# NUC029AN_v1 register map
File version: 1.0
Registers are 32-bit, read-write, reset 0x0 unless marked. A register's access mark holds for its fields unless they carry their own. Offsets are from the block's base; [hi:lo] are bit positions; {n}, {i} and the like mark numbered series.

## GCR — GCR Register Map
Base 0x50000000
0x00 PDID ro reset 0x20005200 — Part Device Identification number Register
  [31:0] PDID — Part Device Identification Number. This register reflects device part number code. S/W can read this register to identify which device is used. For example, M052LCN PDID code is 0x2000_5200.
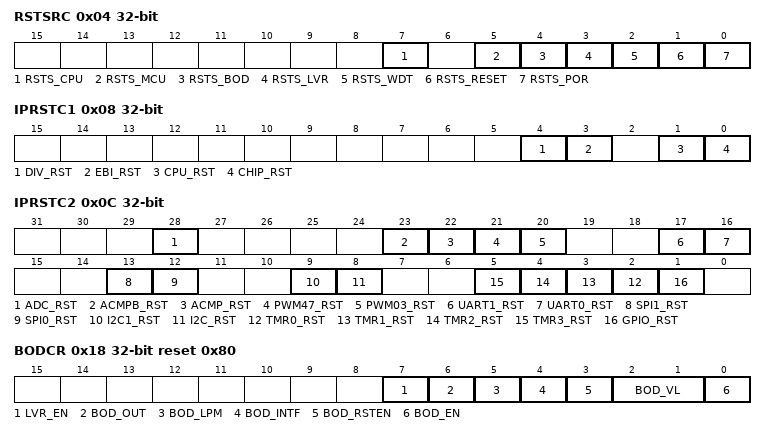
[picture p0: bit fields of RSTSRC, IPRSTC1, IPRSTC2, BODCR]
0x04 RSTSRC (reset mask 0xFFFFFF00) — System Reset Source Register
  [7] RSTS_CPU — The RSTS_CPU flag is set by hardware if software writes CPU_RST (IPRSTC1[1]) 1 to reset Cortex-M0 CPU kernel and Flash memory controller (FMC). Software can write 1 to clear this bit to zero.
    0=No reset from CPU; 1=The Cortex-M0 CPU kernel and FMC are reset by software setting CPU_RST to 1
  [5] RSTS_MCU — The RSTS_MCU flag is set by the "reset signal" from the MCU Cortex_M0 kernel to indicate the previous reset source. This bit is cleared by writing 1 to itself.
    0=No reset from MCU; 1=The MCU Cortex_M0 had issued the reset signal to reset the system by software writing 1 to bit SYSRESTREQ(AIRCR[2], Application Interrupt and Reset Control Register) in system control registers of Cortex_M0 kernel
  [4] RSTS_BOD — The RSTS_BOD flag is set by the "reset signal" from the Brown-Out Detector to indicate the previous reset source. Software can write 1 to clear this bit to zero.
    0=No reset from BOD; 1=The Brown-Out Detector module had issued the reset signal to reset the system
  [3] RSTS_LVR — The RSTS_LVR flag is set by the "reset signal" from the Low-Voltage-Reset controller to indicate the previous reset source. Software can write 1 to clear this bit to zero.
    0=No reset from LVR; 1=The LVR module had issued the reset signal to reset the system
  [2] RSTS_WDT — The RSTS_WDT flag is set by the "reset signal" from the Watchdog timer to indicate the previous reset source. Software can write 1 to clear this bit to zero.
    0=No reset from Watchdog timer; 1=The Watchdog timer had issued the reset signal to reset the system
  [1] RSTS_RESET — The RSTS_RESET flag is set by the "reset signal" from the /RESET pin to indicate the previous reset source. Software can write 1 to clear this bit to zero.
    0=No reset from Pin /RESET; 1=The Pin /RESET had issued the reset signal to reset the system
  [0] RSTS_POR — The RSTS_POR flag is set by the "reset signal", which is from the Power-On Reset (POR) module or bit CHIP_RST (IPRSTC1[0]) is set, to indicate the previous reset source. Software can write 1 to clear this bit to zero.
    0=No reset from POR or CHIP_RST; 1=The Power-On-Reset (POR) or CHIP_RST had issued the reset signal to reset the system
0x08 IPRSTC1 — Peripheral Reset Control Register 1
  [4] DIV_RST — DIV Controller Reset (write-protection bit). Set this bit to 1 will generate a reset signal to the DIVIDER. User need to set this bit to 0 to release from the reset state. This bit is the protected bit, It means programming this bit needs to write "59h", "16h", "88h" to address 0x5000_0100 to disable register protection. Reference the register REGWRPROT at address GCR_BA+0x100
    0=DIVIDER controller normal operation; 1=DIVIDER controller reset
  [3] EBI_RST — EBI Controller Reset (write-protected). Set these bit "1" will generate a reset signal to the EBI. User need to set this bit to "0" to release from the reset state
    0=EBI controller normal operation; 1=EBI controller reset
  [1] CPU_RST — CPU kernel one shot reset (write-protected). Set this bit will reset the Cortex-M0 CPU kernel and Flash memory controller (FMC). This bit will automatically return to "0" after the 2 clock cycles
    0=Normal; 1=Reset CPU
  [0] CHIP_RST — CHIP one shot reset (write-protected). Set this bit will reset the CHIP, including CPU kernel and all peripherals, and this bit will automatically return to "0" after the 2 clock cycles. The CHIP_RST is same as the POR reset , all the chip module is reset and the chip setting from flash are also reload
    0=Normal; 1=Reset CHIP
0x0C IPRSTC2 — Peripheral Reset Control Register 2
  [28] ADC_RST — ADC Controller Reset
    0=ADC controller normal operation; 1=ADC controller reset
  [23] ACMPB_RST — Analog Comparator 1 Controller Reset
    0=Analog Comparator controller 1 normal operation; 1=Analog Comparator controller 1 reset
  [22] ACMP_RST — Analog Comparator Controller Reset
    0=Analog Comparator controller normal operation; 1=Analog Comparator controller reset
  [21] PWM47_RST — PWM4~7 controller Reset
    0=PWM4~7 controller normal operation; 1=PWM4~7 controller reset
  [20] PWM03_RST — PWM0~3 controller Reset
    0=PWM0~3 controller normal operation; 1=PWM0~3 controller reset
  [17] UART1_RST — UART1 controller Reset
    0=UART1 controller normal operation; 1=UART1 controller reset
  [16] UART0_RST — UART0 controller Reset
    0=UART0 controller normal operation; 1=UART0 controller reset
  [13] SPI1_RST — SPI1 controller Reset
    0=SPI1 controller normal operation; 1=SPI1 controller reset
  [12] SPI0_RST — SPI0 controller Reset
    0=SPI0 controller normal operation; 1=SPI0 controller reset
  [9] I2C1_RST — I2C1 controller Reset
    0=I2C1 controller normal operation; 1=I2C1 controller reset
  [8] I2C_RST — I2C0 controller Reset
    0=I2C0 controller normal operation; 1=I2C0 controller reset
  [n+2] TMR{n}_RST (n=0..3) — Timer{n} controller Reset
    0=Timer{n} controller normal operation; 1=Timer{n} controller reset
  [1] GPIO_RST — GPIO (P0~P4) controller Reset
    0=GPIO controller normal operation; 1=GPIO controller reset
0x18 BODCR reset 0x80 (reset mask 0xFFFFFFF0) — Brown-Out Detector Control Register
  [7] LVR_EN — Low Voltage Reset Enable (write-protected). The LVR function reset the chip when the input power voltage is lower than LVR circuit setting. LVR function is enabled in default.
    0=Disabled Low Voltage Reset function; 1=Enabled Low Voltage Reset function - After enabling the bit, the LVR function will be active with 100uS delay for LVR output stable. (Default)
  [6] BOD_OUT — Brown-Out Detector output status
    0=Brown-Out Detector output status is 0. It means the detected voltage is higher than BOD_VL setting or BOD_EN is 0; 1=Brown-Out Detector output status is 1. It means the detected voltage is lower than BOD_VL setting. If the BOD_EN is 0, BOD function disabled , this bit always responds 0
  [5] BOD_LPM — Brown-Out Detector Low power Mode (write-protected). The BOD consumes about 100uA in normal mode, the low power mode can reduce the current to about 1/10 but slow the BOD response.
    0=BOD operate in normal mode (default); 1=Enable the BOD low power mode
  [4] BOD_INTF — Brown-Out Detector Interrupt Flag. Software can write 1 to clear this bit to zero.
    0=Brown-Out Detector does not detect any voltage draft at VDD down through or up through the voltage of BOD_VL setting; 1=When Brown-Out Detector detects the VDD is dropped down through the voltage of BOD_VL setting or the VDD is raised up through the voltage of BOD_VL setting, this bit is set to 1 and the Brown-Out interrupt is requested if Brown-Out interrupt is enabled
  [3] BOD_RSTEN — Brown-Out Reset Enable (write-protected). The default value is set by flash controller user configuration register config0 bit[20].
    0=Enable the Brown-Out "INTERRUPT" function.While the BOD function is enabled (BOD_EN high) and BOD interrupt function is enabled (BOD_RSTEN low), BOD will assert an interrupt if BOD_OUT is high. BOD interrupt will keep till to the BOD_EN set to 0. BOD interrupt can be blocked by disabling the NVIC BOD interrupt or disabling BOD function (set BOD_EN low); 1=Enable the Brown-Out "RESET" function. While the Brown-Out Detector function is enabled (BOD_EN high) and BOD reset function is enabled (BOD_RSTEN high), BOD will assert a signal to reset chip when the detected voltage is lower than the threshold (BOD_OUT high)
  [2:1] BOD_VL — Brown-Out Detector Threshold Voltage Selection (write-protected)
  [0] BOD_EN — Brown-Out Detector Enable (write-protected). The default value is set by flash controller user configuration register config0 bit[23]
    0=Brown-Out Detector function is disabled; 1=Brown-Out Detector function is enabled
0x1C TEMPCR — Temperature Sensor Control Register
  [0] VTEMP_EN — Temperature sensor Enable. This bit is used to enable/disable temperature sensor function. After this bit is set to 1, the value of temperature can get from ADC conversion result by ADC channel selecting channel 7 and alternative multiplexer channel selecting temperature sensor. Detail ADC conversion function please reference ADC function chapter.
    0=Disabled temperature sensor function (default); 1=Enabled temperature sensor function
0x24 PORCR (reset mask 0xFFFFFF00) — Power-On-Reset Controller Register
  [15:0] POR_DIS_CODE — Power-On-Reset enable control (write-protected). When power on, the POR circuit generates a reset signal to reset the whole chip function, but noise on the power may cause the POR active again. If set the POR_DIS_CODE equal to 0x5AA5, the POR reset function will be disabled and the POR function will re-active till the power voltage is lower to set the POR_DIS_CODE to another value or reset by chip other reset function. Include: /RESET, Watch dog, LVR reset BOD reset, ICE reset command and the software-chip reset function.
0x28 GPIO_2CKn — GPIO 2CK Strong Pull High Controller Register
  [0] GPIO_2CKn — GPIO two clock strong pull high disable
    0=GPIO two clock strong pull high is enabled if Pxx_DOUT is 0 before reset; 1=GPIO two clock strong pull high is disabled if Pxx_DOUT is 0 before reset
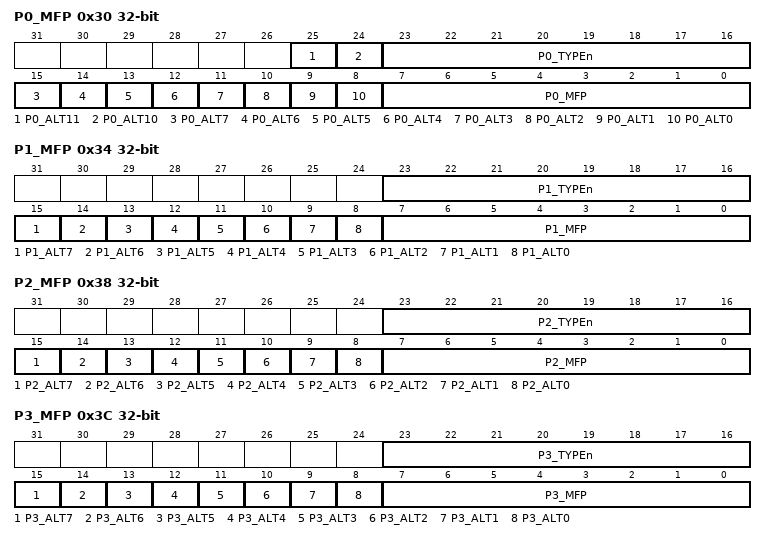
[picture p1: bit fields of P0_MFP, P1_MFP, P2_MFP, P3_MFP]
0x30 P0_MFP — P0 multiple function and input type control register
  [25] P0_ALT11 — P0.1 alternate function Selection1. The pin function of P0.1 depends on P0_MFP[1], P0_ALT[1], and P0_ALT1[1]. Refer to P0_ALT[1] for details descriptions.
  [24] P0_ALT10 — P0.0 alternate function Selection1. The pin function of P0.0 depends on P0_MFP[0], P0_ALT[0], and P0_ALT1[0]. Refer to P0_ALT[0] for details descriptions.
  [23:16] P0_TYPEn — P0[7:0] input Schmitt Trigger function Enable
    0=Disable P0[7:0] I/O input Schmitt Trigger function; 1=Enable P0[7:0] I/O input Schmitt Trigger function
  [15] P0_ALT7 — P0.7 alternate function Selection
  [14] P0_ALT6 — P0.6 alternate function Selection
  [13] P0_ALT5 — P0.5 alternate function Selection
  [12] P0_ALT4 — P0.4 alternate function Selection
  [11] P0_ALT3 — P0.3 alternate function Selection
  [10] P0_ALT2 — P0.2 alternate function Selection
  [9] P0_ALT1 — P0.1 alternate function Selection
  [8] P0_ALT0 — P0.0 alternate function Selection
  [7:0] P0_MFP — P0 multiple function Selection. The pin function of P0 depends on P0_MFP and P0_ALT. Refer to P0_ALT for details descriptions.
0x34 P1_MFP — P1 multiple function and input type control register
  [23:16] P1_TYPEn — P1[7:0] input Schmitt Trigger function Enable
    0=Disable P1[7:0] I/O input Schmitt Trigger function; 1=Enable P1[7:0] I/O input Schmitt Trigger function
  [15] P1_ALT7 — P1.7 alternate function Selection
  [14] P1_ALT6 — P1.6 alternate function Selection
  [13] P1_ALT5 — P1.5 alternate function Selection
  [12] P1_ALT4 — P1.4 alternate function Selection
  [11] P1_ALT3 — P1.3 alternate function Selection
  [10] P1_ALT2 — P1.2 alternate function Selection
  [9] P1_ALT1 — P1.1 alternate function Selection
  [8] P1_ALT0 — P1.0 alternate function Selection
  [7:0] P1_MFP — P1 multiple function Selection. The pin function of P1 is depending on P1_MFP and P1_ALT. Refer to P1_ALT for details descriptions.
0x38 P2_MFP — P2 multiple function and input type control register
  [23:16] P2_TYPEn — P2[7:0] input Schmitt Trigger function Enable
    0=Disable P2[7:0] I/O input Schmitt Trigger function; 1=Enable P2[7:0] I/O input Schmitt Trigger function
  [15] P2_ALT7 — P2.7 alternate function Selection
  [14] P2_ALT6 — P2.6 alternate function Selection
  [13] P2_ALT5 — P2.5 alternate function Selection
  [12] P2_ALT4 — P2.4 alternate function Selection
  [11] P2_ALT3 — P2.3 alternate function Selection
  [10] P2_ALT2 — P2.2 alternate function Selection
  [9] P2_ALT1 — P2.1 alternate function Selection
  [8] P2_ALT0 — P2.0 alternate function Selection
  [7:0] P2_MFP — P2 multiple function Selection. The pin function of P2 depends on P2_MFP and P2_ALT. Refer to P2_ALT for details descriptions.
0x3C P3_MFP — P3 multiple function and input type control register
  [23:16] P3_TYPEn — P3[7:0] input Schmitt Trigger function Enable
    0=Disable P3[7:0] I/O input Schmitt Trigger function; 1=Enable P3[7:0] I/O input Schmitt Trigger function
  [15] P3_ALT7 — P3.7 alternate function Selection
  [14] P3_ALT6 — P3.6 alternate function Selection
  [13] P3_ALT5 — P3.5 alternate function Selection
  [12] P3_ALT4 — P3.4 alternate function Selection
  [11] P3_ALT3 — P3.3 alternate function Selection
  [10] P3_ALT2 — P3.2 alternate function Selection
  [9] P3_ALT1 — P3.1 alternate function Selection
  [8] P3_ALT0 — P3.0 alternate function Selection
  [7:0] P3_MFP — P3 multiple function Selection. The pin function of P3 is depending on P3_MFP and P3_ALT. Refer to P3_ALT for details descriptions.
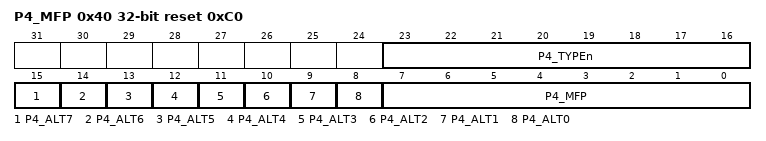
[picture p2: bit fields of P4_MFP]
0x40 P4_MFP reset 0xC0 — P4 multiple function and input type control register
  [23:16] P4_TYPEn — P4[7:0] input Schmitt Trigger function Enable
    0=Disable P4[7:0] I/O input Schmitt Trigger function disable; 1=Enable P4[7:0] I/O input Schmitt Trigger function enable
  [15] P4_ALT7 — P4.7 alternate function Selection
  [14] P4_ALT6 — P4.6 alternate function Selection
  [13] P4_ALT5 — P4.5 alternate function Selection
  [12] P4_ALT4 — P4.4 alternate function Selection
  [11] P4_ALT3 — P4.3 alternate function Selection
  [10] P4_ALT2 — P4.2 alternate function Selection
  [9] P4_ALT1 — P4.1 alternate function Selection
  [8] P4_ALT0 — P4.0 alternate function Selection
  [7:0] P4_MFP — P4 multiple function Selection. The pin function of P4 is depending on P4_MFP and P4_ALT. Refer to P4_ALT for details descriptions.
0x100 REGWRPROT — Register Write-Protection Control Register
  [0] REGPROTDIS ro — Register Write-Protected Disable index (Read only)
    0=Protection is enabled for writing protected registers. Any write to the protected register is ignored; 1=Protection is disabled for writing protected registers
  [7:0] REGWRPROT wo — Register Write-Protected Code (Write Only). Programming a write-protected register, must remove write-protected function by programming a sequence of value "59h", "16h", "88h" to this field. After this sequence is completed, the REGPROTDIS bit will be set to 1 and write-protected registers can be normal written.
